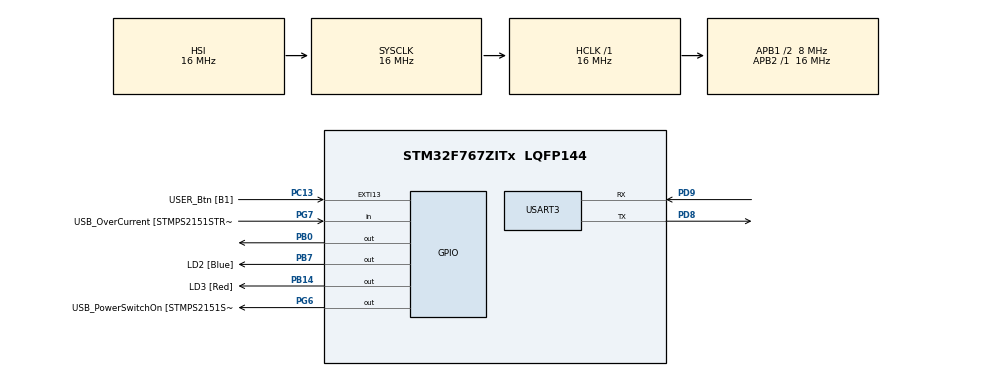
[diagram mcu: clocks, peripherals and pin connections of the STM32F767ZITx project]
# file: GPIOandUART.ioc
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Mcu.Family=STM32F7
Mcu.Name=STM32F767ZITx
Mcu.Package=LQFP144
NVIC.PriorityGroup=NVIC_PRIORITYGROUP_4
NVIC.USART3_IRQn=true\:0\:0\:false\:false\:true\:true\:true
PB0.Signal=GPIO_Output
PB14.GPIO_Label=LD3 [Red]
PB14.Signal=GPIO_Output
PB7.GPIO_Label=LD2 [Blue]
PB7.Signal=GPIO_Output
PC13.GPIO_Label=USER_Btn [B1]
PC13.Signal=GPXTI13
PD8.Mode=Asynchronous
PD8.Signal=USART3_TX
PD9.Mode=Asynchronous
PD9.Signal=USART3_RX
PG6.GPIO_Label=USB_PowerSwitchOn [STMPS2151STR_EN]
PG6.Signal=GPIO_Output
PG7.GPIO_Label=USB_OverCurrent [STMPS2151STR_FAULT]
PG7.Signal=GPIO_Input
ProjectManager.HeapSize=0x200
ProjectManager.StackSize=0x400
ProjectManager.TargetToolchain=Makefile
RCC.48MHZClocksFreq_Value=24000000
RCC.AHBFreq_Value=16000000
RCC.APB1CLKDivider=RCC_HCLK_DIV2
RCC.APB1Freq_Value=8000000
RCC.APB1TimFreq_Value=16000000
RCC.APB2Freq_Value=16000000
RCC.APB2TimFreq_Value=16000000
RCC.CortexFreq_Value=16000000
RCC.HCLKFreq_Value=16000000
RCC.HSE_VALUE=16000000
RCC.HSI_VALUE=16000000
RCC.LSE_VALUE=32768
RCC.PLLMUL=RCC_PLL_MUL9
RCC.PRESCALERUSB=RCC_USBCLKSOURCE_PLL_DIV1_5
RCC.SYSCLKFreq_VALUE=16000000
RCC.SYSCLKSourceVirtual=RCC_SYSCLKSOURCE_PLLCLK
RCC.USBFreq_Value=96000000
RCC.VCOOutputFreq_Value=192000000
USART3.VirtualMode-Asynchronous=VM_ASYNC
board=NUCLEO-F767ZI

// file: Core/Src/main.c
/* USER CODE BEGIN Header */
/**
  ******************************************************************************
  * @file           : main.c
  * @brief          : Main program body
  ******************************************************************************
  * @attention
  *
  * <h2><center>&copy; Copyright (c) 2021 STMicroelectronics.
  * All rights reserved.</center></h2>
  *
  * This software component is licensed by ST under BSD 3-Clause license,
  * the "License"; You may not use this file except in compliance with the
  * License. You may obtain a copy of the License at:
  *                        opensource.org/licenses/BSD-3-Clause
  *
  ******************************************************************************
  */
/* USER CODE END Header */
#include "main.h"
#include "usart.h"
#include "gpio.h"

void SystemClock_Config(void);

int main(void)
{

  /* MCU Configuration--------------------------------------------------------*/

  /* Reset of all peripherals, Initializes the Flash interface and the Systick. */
  HAL_Init();

  /* Configure the system clock */
  SystemClock_Config();

  /* Initialize all configured peripherals */
  MX_GPIO_Init();
  MX_USART3_UART_Init();
  /* USER CODE BEGIN 2 */

	uint8_t *ptr = NULL;
	int res = 0;
	init_UART3Receive();
	printf("hello stm32 \r\n");
	printf("type a message and press enter\r\n");

  /* USER CODE END 2 */

  /* Infinite loop */
  /* USER CODE BEGIN WHILE */
  while (1)
  {
		// a cada byte recebido, guardar na fifo (\n)
		//L_GPIO_LockPin
		HAL_GPIO_TogglePin(GPIOB, GPIO_PIN_7); //blue led
		newMessage();
		if(receive_flag){
			receive_flag = 0;
			printf("the message was:  \%s\\ \n", Rx_Buffer);
			printf("type another message and press enter\r\n");
			//res = validar(ptr);
			printf("Resultado: 5E: %d ", res);
		HAL_GPIO_TogglePin(GPIOB, GPIO_PIN_14);	 //red
		}
		HAL_Delay(100);
    /* USER CODE END WHILE */

  }
}

void SystemClock_Config(void)
{
  RCC_OscInitTypeDef RCC_OscInitStruct = {0};
  RCC_ClkInitTypeDef RCC_ClkInitStruct = {0};
  RCC_PeriphCLKInitTypeDef PeriphClkInitStruct = {0};

  /** Configure the main internal regulator output voltage
  */
  __HAL_RCC_PWR_CLK_ENABLE();
  __HAL_PWR_VOLTAGESCALING_CONFIG(PWR_REGULATOR_VOLTAGE_SCALE3);
  /** Initializes the RCC Oscillators according to the specified parameters
  * in the RCC_OscInitTypeDef structure.
  */
  RCC_OscInitStruct.OscillatorType = RCC_OSCILLATORTYPE_HSI;
  RCC_OscInitStruct.HSIState = RCC_HSI_ON;
  RCC_OscInitStruct.HSICalibrationValue = RCC_HSICALIBRATION_DEFAULT;
  RCC_OscInitStruct.PLL.PLLState = RCC_PLL_NONE;
  if (HAL_RCC_OscConfig(&RCC_OscInitStruct) != HAL_OK)
  {
    Error_Handler();
  }
  /** Initializes the CPU, AHB and APB buses clocks
  */
  RCC_ClkInitStruct.ClockType = RCC_CLOCKTYPE_HCLK|RCC_CLOCKTYPE_SYSCLK
                              |RCC_CLOCKTYPE_PCLK1|RCC_CLOCKTYPE_PCLK2;
  RCC_ClkInitStruct.SYSCLKSource = RCC_SYSCLKSOURCE_HSI;
  RCC_ClkInitStruct.AHBCLKDivider = RCC_SYSCLK_DIV1;
  RCC_ClkInitStruct.APB1CLKDivider = RCC_HCLK_DIV2;
  RCC_ClkInitStruct.APB2CLKDivider = RCC_HCLK_DIV1;

  if (HAL_RCC_ClockConfig(&RCC_ClkInitStruct, FLASH_LATENCY_0) != HAL_OK)
  {
    Error_Handler();
  }
  PeriphClkInitStruct.PeriphClockSelection = RCC_PERIPHCLK_USART3;
  PeriphClkInitStruct.Usart3ClockSelection = RCC_USART3CLKSOURCE_PCLK1;
  if (HAL_RCCEx_PeriphCLKConfig(&PeriphClkInitStruct) != HAL_OK)
  {
    Error_Handler();
  }
}

void Error_Handler(void)
{
  __disable_irq();
  while (1)
  {
  }
}

/************************ (C) COPYRIGHT STMicroelectronics *****END OF FILE****/
